# PIC32MZ0512EFF144 device description
Architecture: 32xxxx; Family: PIC32MZEF; Series: PIC32MZ
Registers are 32-bit, read-write, no defined reset value unless marked. A register's access mark holds for its fields unless they carry their own. Offsets are from the block's base; [hi:lo] are bit positions; {n}, {i} and the like mark numbered series; 'fields as' and 'values as' point back to an identical list.

## GPIO
Instances: GPIO 0x1f860000 in periph_pb4_std
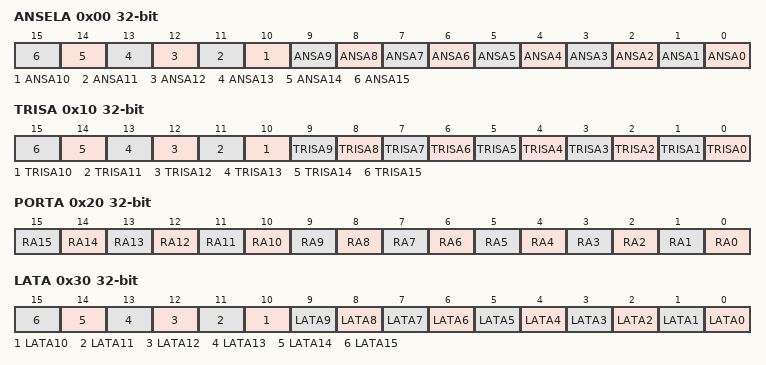
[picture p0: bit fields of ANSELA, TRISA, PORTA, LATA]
0x00 ANSELA
  [n] ANSA{n} (n=0..15)
0x10 TRISA
  [n] TRISA{n} (n=0..15)
0x20 PORTA
  [n] RA{n} (n=0..15)
0x30 LATA
  [n] LATA{n} (n=0..15)
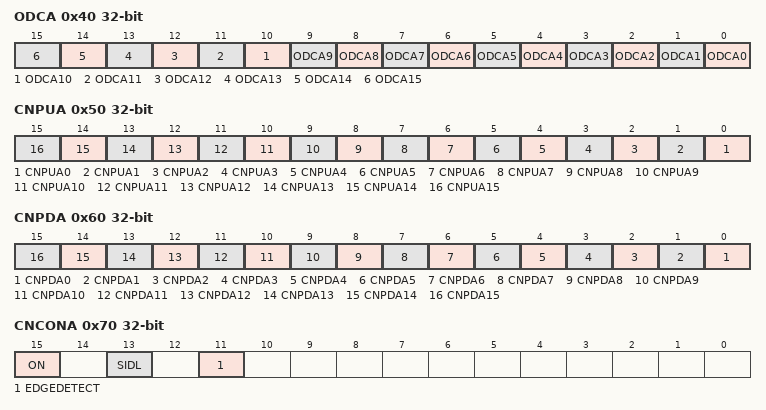
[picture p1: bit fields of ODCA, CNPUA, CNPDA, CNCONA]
0x40 ODCA
  [n] ODCA{n} (n=0..15)
0x50 CNPUA
  [n] CNPUA{n} (n=0..15)
0x60 CNPDA
  [n] CNPDA{n} (n=0..15)
0x70 CNCONA — Change Notice control for PORTx Register
  [15] ON — Change Notice Control ON bit
    1=CN is enabled; 0=CN is disabled
  [13] SIDL
  [11] EDGEDETECT — Change Notification Style bit
    1=Edge Style. Detect edge transitions (CNFx used for CN Event).; 0=Mismatch Style. Detect change from last PORTx read (CNSTATx used for CN Event).
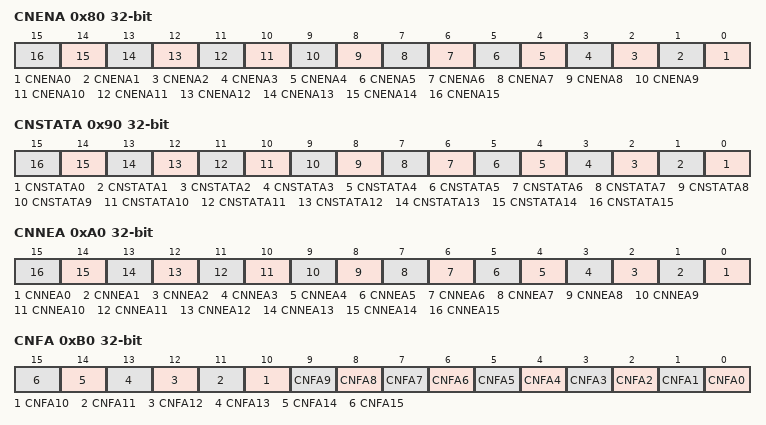
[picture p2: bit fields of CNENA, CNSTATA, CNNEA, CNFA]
0x80 CNENA
  [n] CNENA{n} (n=0..15)
0x90 CNSTATA
  [n] CNSTATA{n} (n=0..15)
0xA0 CNNEA
  [n] CNNEA{n} (n=0..15)
0xB0 CNFA
  [n] CNFA{n} (n=0..15)
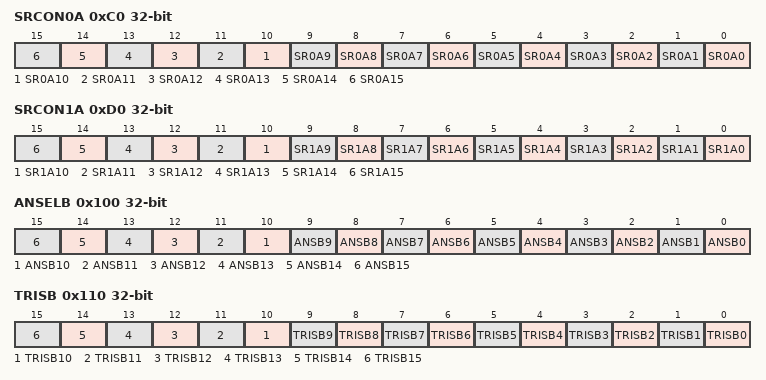
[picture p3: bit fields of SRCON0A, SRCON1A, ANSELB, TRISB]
0xC0 SRCON0A
  [n] SR0A{n} (n=0..15)
0xD0 SRCON1A
  [n] SR1A{n} (n=0..15)
0x100 ANSELB
  [n] ANSB{n} (n=0..15)
0x110 TRISB
  [n] TRISB{n} (n=0..15)
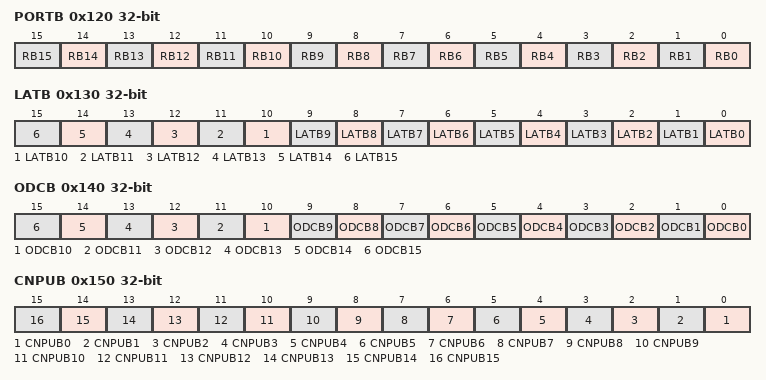
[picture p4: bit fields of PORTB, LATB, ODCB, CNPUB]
0x120 PORTB
  [n] RB{n} (n=0..15)
0x130 LATB
  [n] LATB{n} (n=0..15)
0x140 ODCB
  [n] ODCB{n} (n=0..15)
0x150 CNPUB
  [n] CNPUB{n} (n=0..15)
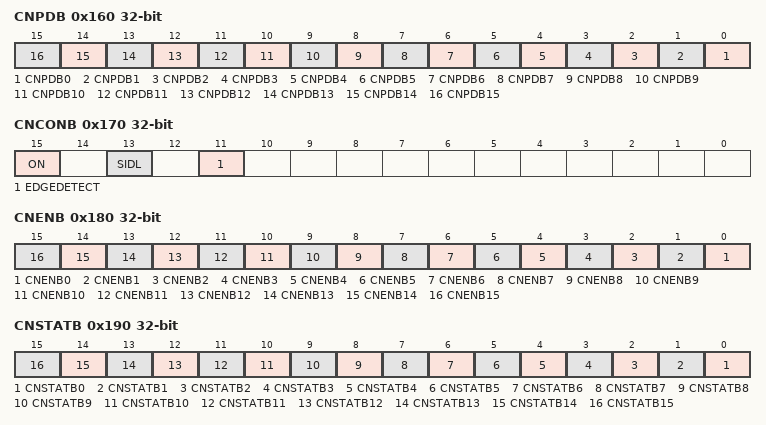
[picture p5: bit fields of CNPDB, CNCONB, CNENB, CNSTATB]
0x160 CNPDB
  [n] CNPDB{n} (n=0..15)
0x170 CNCONB — Change Notice control for PORTx Register
  fields as CNCONA
0x180 CNENB
  [n] CNENB{n} (n=0..15)
0x190 CNSTATB
  [n] CNSTATB{n} (n=0..15)
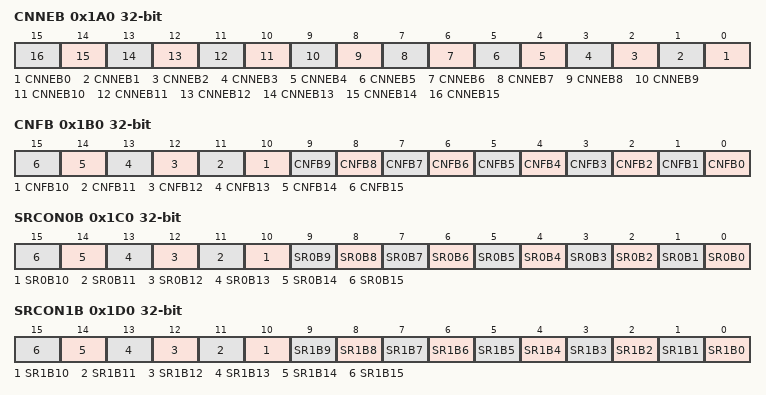
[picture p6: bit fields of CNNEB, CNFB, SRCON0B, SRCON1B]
0x1A0 CNNEB
  [n] CNNEB{n} (n=0..15)
0x1B0 CNFB
  [n] CNFB{n} (n=0..15)
0x1C0 SRCON0B
  [n] SR0B{n} (n=0..15)
0x1D0 SRCON1B
  [n] SR1B{n} (n=0..15)
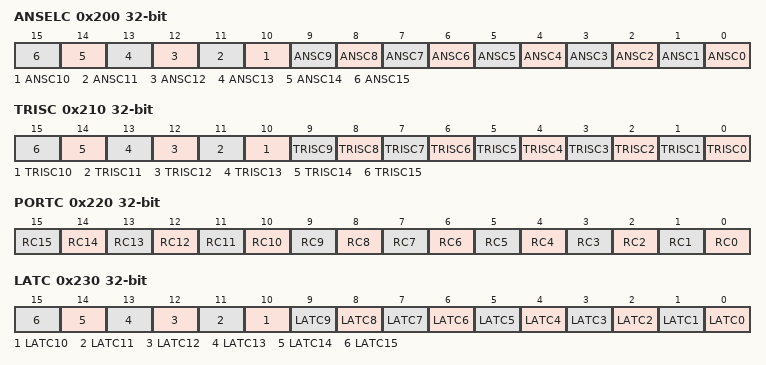
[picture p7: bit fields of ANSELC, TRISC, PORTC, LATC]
0x200 ANSELC
  [n] ANSC{n} (n=0..15)
0x210 TRISC
  [n] TRISC{n} (n=0..15)
0x220 PORTC
  [n] RC{n} (n=0..15)
0x230 LATC
  [n] LATC{n} (n=0..15)
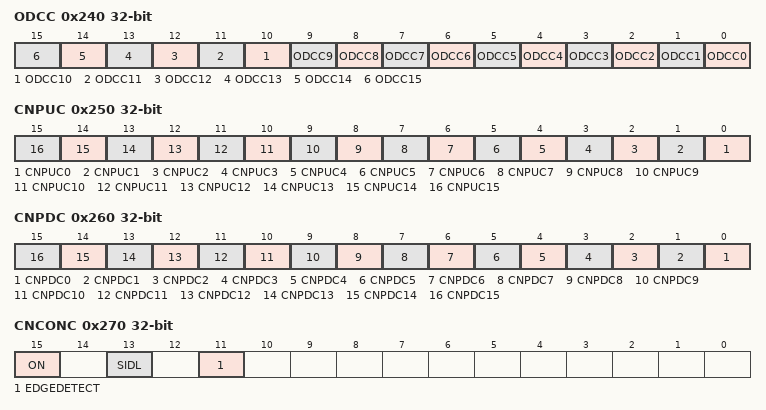
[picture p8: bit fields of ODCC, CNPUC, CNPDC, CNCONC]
0x240 ODCC
  [n] ODCC{n} (n=0..15)
0x250 CNPUC
  [n] CNPUC{n} (n=0..15)
0x260 CNPDC
  [n] CNPDC{n} (n=0..15)
0x270 CNCONC — Change Notice control for PORTx Register
  fields as CNCONA
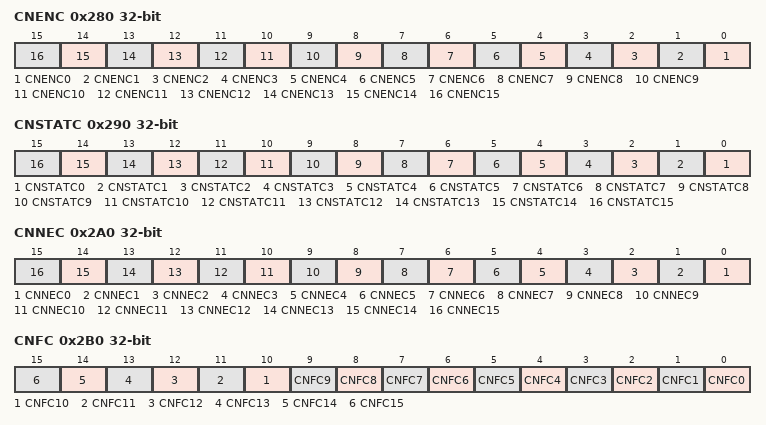
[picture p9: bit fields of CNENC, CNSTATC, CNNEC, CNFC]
0x280 CNENC
  [n] CNENC{n} (n=0..15)
0x290 CNSTATC
  [n] CNSTATC{n} (n=0..15)
0x2A0 CNNEC
  [n] CNNEC{n} (n=0..15)
0x2B0 CNFC
  [n] CNFC{n} (n=0..15)
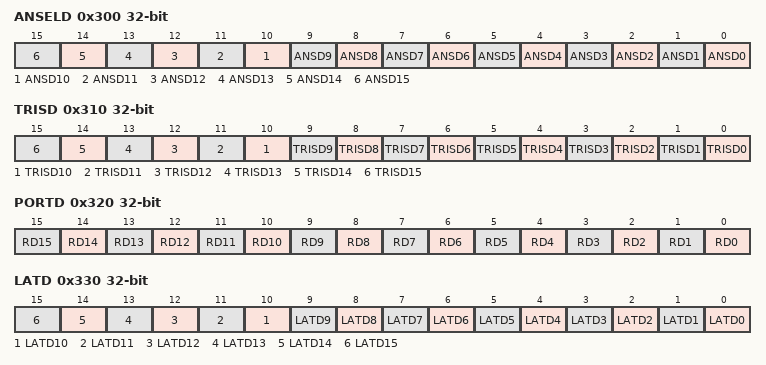
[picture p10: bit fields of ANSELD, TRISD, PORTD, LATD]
0x300 ANSELD
  [n] ANSD{n} (n=0..15)
0x310 TRISD
  [n] TRISD{n} (n=0..15)
0x320 PORTD
  [n] RD{n} (n=0..15)
0x330 LATD
  [n] LATD{n} (n=0..15)
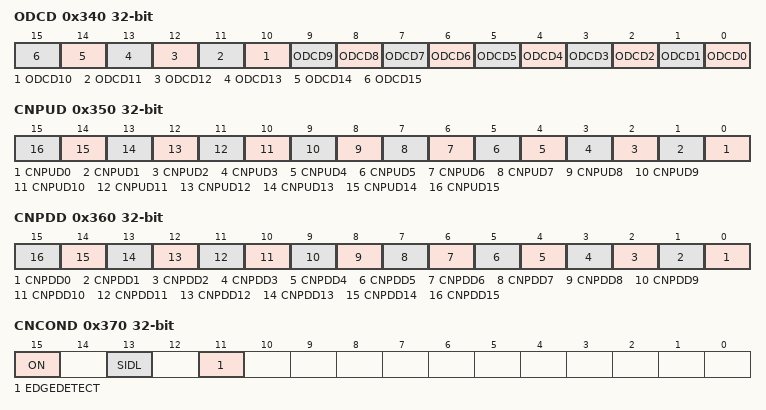
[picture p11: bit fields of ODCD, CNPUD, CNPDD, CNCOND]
0x340 ODCD
  [n] ODCD{n} (n=0..15)
0x350 CNPUD
  [n] CNPUD{n} (n=0..15)
0x360 CNPDD
  [n] CNPDD{n} (n=0..15)
0x370 CNCOND — Change Notice control for PORTx Register
  fields as CNCONA
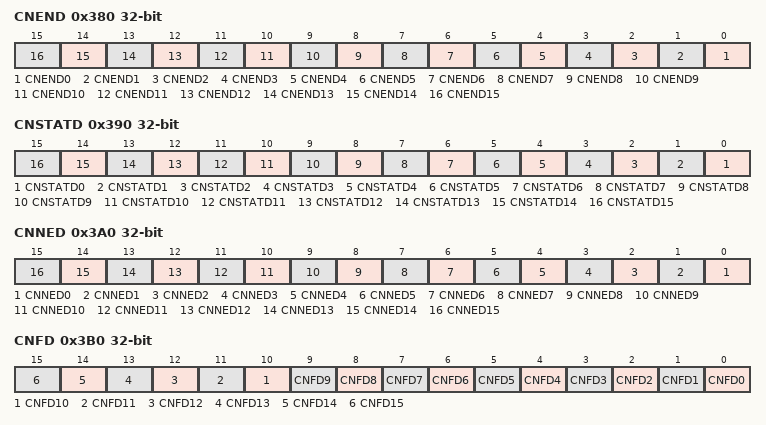
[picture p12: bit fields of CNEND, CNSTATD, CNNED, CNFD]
0x380 CNEND
  [n] CNEND{n} (n=0..15)
0x390 CNSTATD
  [n] CNSTATD{n} (n=0..15)
0x3A0 CNNED
  [n] CNNED{n} (n=0..15)
0x3B0 CNFD
  [n] CNFD{n} (n=0..15)
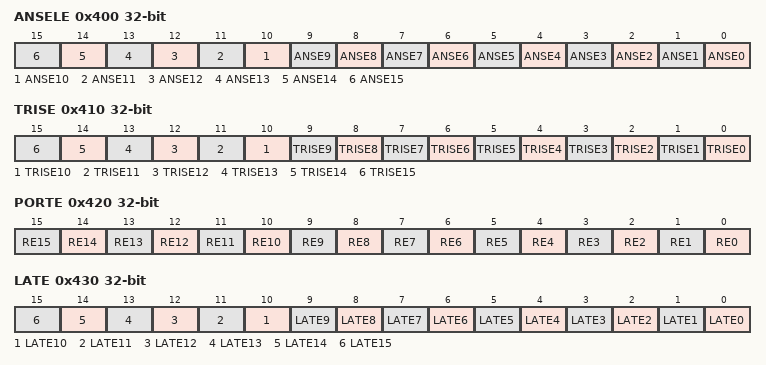
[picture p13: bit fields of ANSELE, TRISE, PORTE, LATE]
0x400 ANSELE
  [n] ANSE{n} (n=0..15)
0x410 TRISE
  [n] TRISE{n} (n=0..15)
0x420 PORTE
  [n] RE{n} (n=0..15)
0x430 LATE
  [n] LATE{n} (n=0..15)
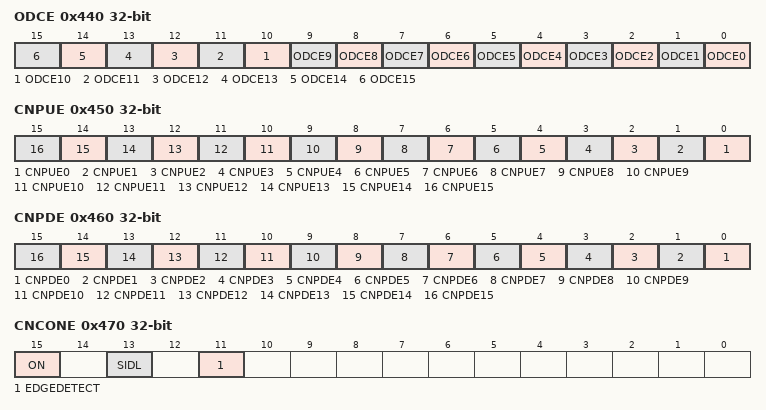
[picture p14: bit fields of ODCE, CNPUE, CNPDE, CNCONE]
0x440 ODCE
  [n] ODCE{n} (n=0..15)
0x450 CNPUE
  [n] CNPUE{n} (n=0..15)
0x460 CNPDE
  [n] CNPDE{n} (n=0..15)
0x470 CNCONE — Change Notice control for PORTx Register
  fields as CNCONA
0x480 CNENE
  [n] CNENE{n} (n=0..15)
0x490 CNSTATE
  [n] CNSTATE{n} (n=0..15)
0x4A0 CNNEE
  [n] CNNEE{n} (n=0..15)
0x4B0 CNFE
  [n] CNFE{n} (n=0..15)
0x4C0 SRCON0E
  [n] SR0E{n} (n=0..15)
0x4D0 SRCON1E
  [n] SR1E{n} (n=0..15)
0x500 ANSELF
  [n] ANSF{n} (n=0..15)
0x510 TRISF
  [n] TRISF{n} (n=0..15)
0x520 PORTF
  [n] RF{n} (n=0..15)
0x530 LATF
  [n] LATF{n} (n=0..15)
0x540 ODCF
  [n] ODCF{n} (n=0..15)
0x550 CNPUF
  [n] CNPUF{n} (n=0..15)
0x560 CNPDF
  [n] CNPDF{n} (n=0..15)
0x570 CNCONF — Change Notice control for PORTx Register
  fields as CNCONA
0x580 CNENF
  [n] CNENF{n} (n=0..15)
0x590 CNSTATF
  [n] CNSTATF{n} (n=0..15)
0x5A0 CNNEF
  [n] CNNEF{n} (n=0..15)
0x5B0 CNFF
  [n] CNFF{n} (n=0..15)
0x5C0 SRCON0F
  [n] SR0F{n} (n=0..15)
0x5D0 SRCON1F
  [n] SR1F{n} (n=0..15)
0x600 ANSELG
  [n] ANSG{n} (n=0..15)
0x610 TRISG
  [n] TRISG{n} (n=0..15)
0x620 PORTG
  [n] RG{n} (n=0..15)
0x630 LATG
  [n] LATG{n} (n=0..15)
0x640 ODCG
  [n] ODCG{n} (n=0..15)
0x650 CNPUG
  [n] CNPUG{n} (n=0..15)
0x660 CNPDG
  [n] CNPDG{n} (n=0..15)
0x670 CNCONG — Change Notice control for PORTx Register
  fields as CNCONA
0x680 CNENG
  [n] CNENG{n} (n=0..15)
0x690 CNSTATG
  [n] CNSTATG{n} (n=0..15)
0x6A0 CNNEG
  [n] CNNEG{n} (n=0..15)
0x6B0 CNFG
  [n] CNFG{n} (n=0..15)
0x6C0 SRCON0G
  [n] SR0G{n} (n=0..15)
0x6D0 SRCON1G
  [n] SR1G{n} (n=0..15)
0x700 ANSELH
  [n] ANSH{n} (n=0..15)
0x710 TRISH
  [n] TRISH{n} (n=0..15)
0x720 PORTH
  [n] RH{n} (n=0..15)
0x730 LATH
  [n] LATH{n} (n=0..15)
0x740 ODCH
  [n] ODCH{n} (n=0..15)
0x750 CNPUH
  [n] CNPUH{n} (n=0..15)
0x760 CNPDH
  [n] CNPDH{n} (n=0..15)
0x770 CNCONH — Change Notice control for PORTx Register
  fields as CNCONA
0x780 CNENH
  [n] CNENH{n} (n=0..15)
0x790 CNSTATH
  [n] CNSTATH{n} (n=0..15)
0x7A0 CNNEH
  [n] CNNEH{n} (n=0..15)
0x7B0 CNFH
  [n] CNFH{n} (n=0..15)
0x800 ANSELJ
  [n] ANSJ{n} (n=0..15)
0x810 TRISJ
  [n] TRISJ{n} (n=0..15)
0x820 PORTJ
  [n] RJ{n} (n=0..15)
0x830 LATJ
  [n] LATJ{n} (n=0..15)
0x840 ODCJ
  [n] ODCJ{n} (n=0..15)
0x850 CNPUJ
  [n] CNPUJ{n} (n=0..15)
0x860 CNPDJ
  [n] CNPDJ{n} (n=0..15)
0x870 CNCONJ — Change Notice control for PORTx Register
  fields as CNCONA
0x880 CNENJ
  [n] CNENJ{n} (n=0..15)
0x890 CNSTATJ
  [n] CNSTATJ{n} (n=0..15)
0x8A0 CNNEJ
  [n] CNNEJ{n} (n=0..15)
0x8B0 CNFJ
  [n] CNFJ{n} (n=0..15)
0x910 TRISK
  [n] TRISK{n} (n=0..15)
0x920 PORTK
  [n] RK{n} (n=0..15)
0x930 LATK
  [n] LATK{n} (n=0..15)
0x940 ODCK
  [n] ODCK{n} (n=0..15)
0x950 CNPUK
  [n] CNPUK{n} (n=0..15)
0x960 CNPDK
  [n] CNPDK{n} (n=0..15)
0x970 CNCONK — Change Notice control for PORTx Register
  fields as CNCONA
0x980 CNENK
  [n] CNENK{n} (n=0..15)
0x990 CNSTATK
  [n] CNSTATK{n} (n=0..15)
0x9A0 CNNEK
  [n] CNNEK{n} (n=0..15)
0x9B0 CNFK
  [n] CNFK{n} (n=0..15)
